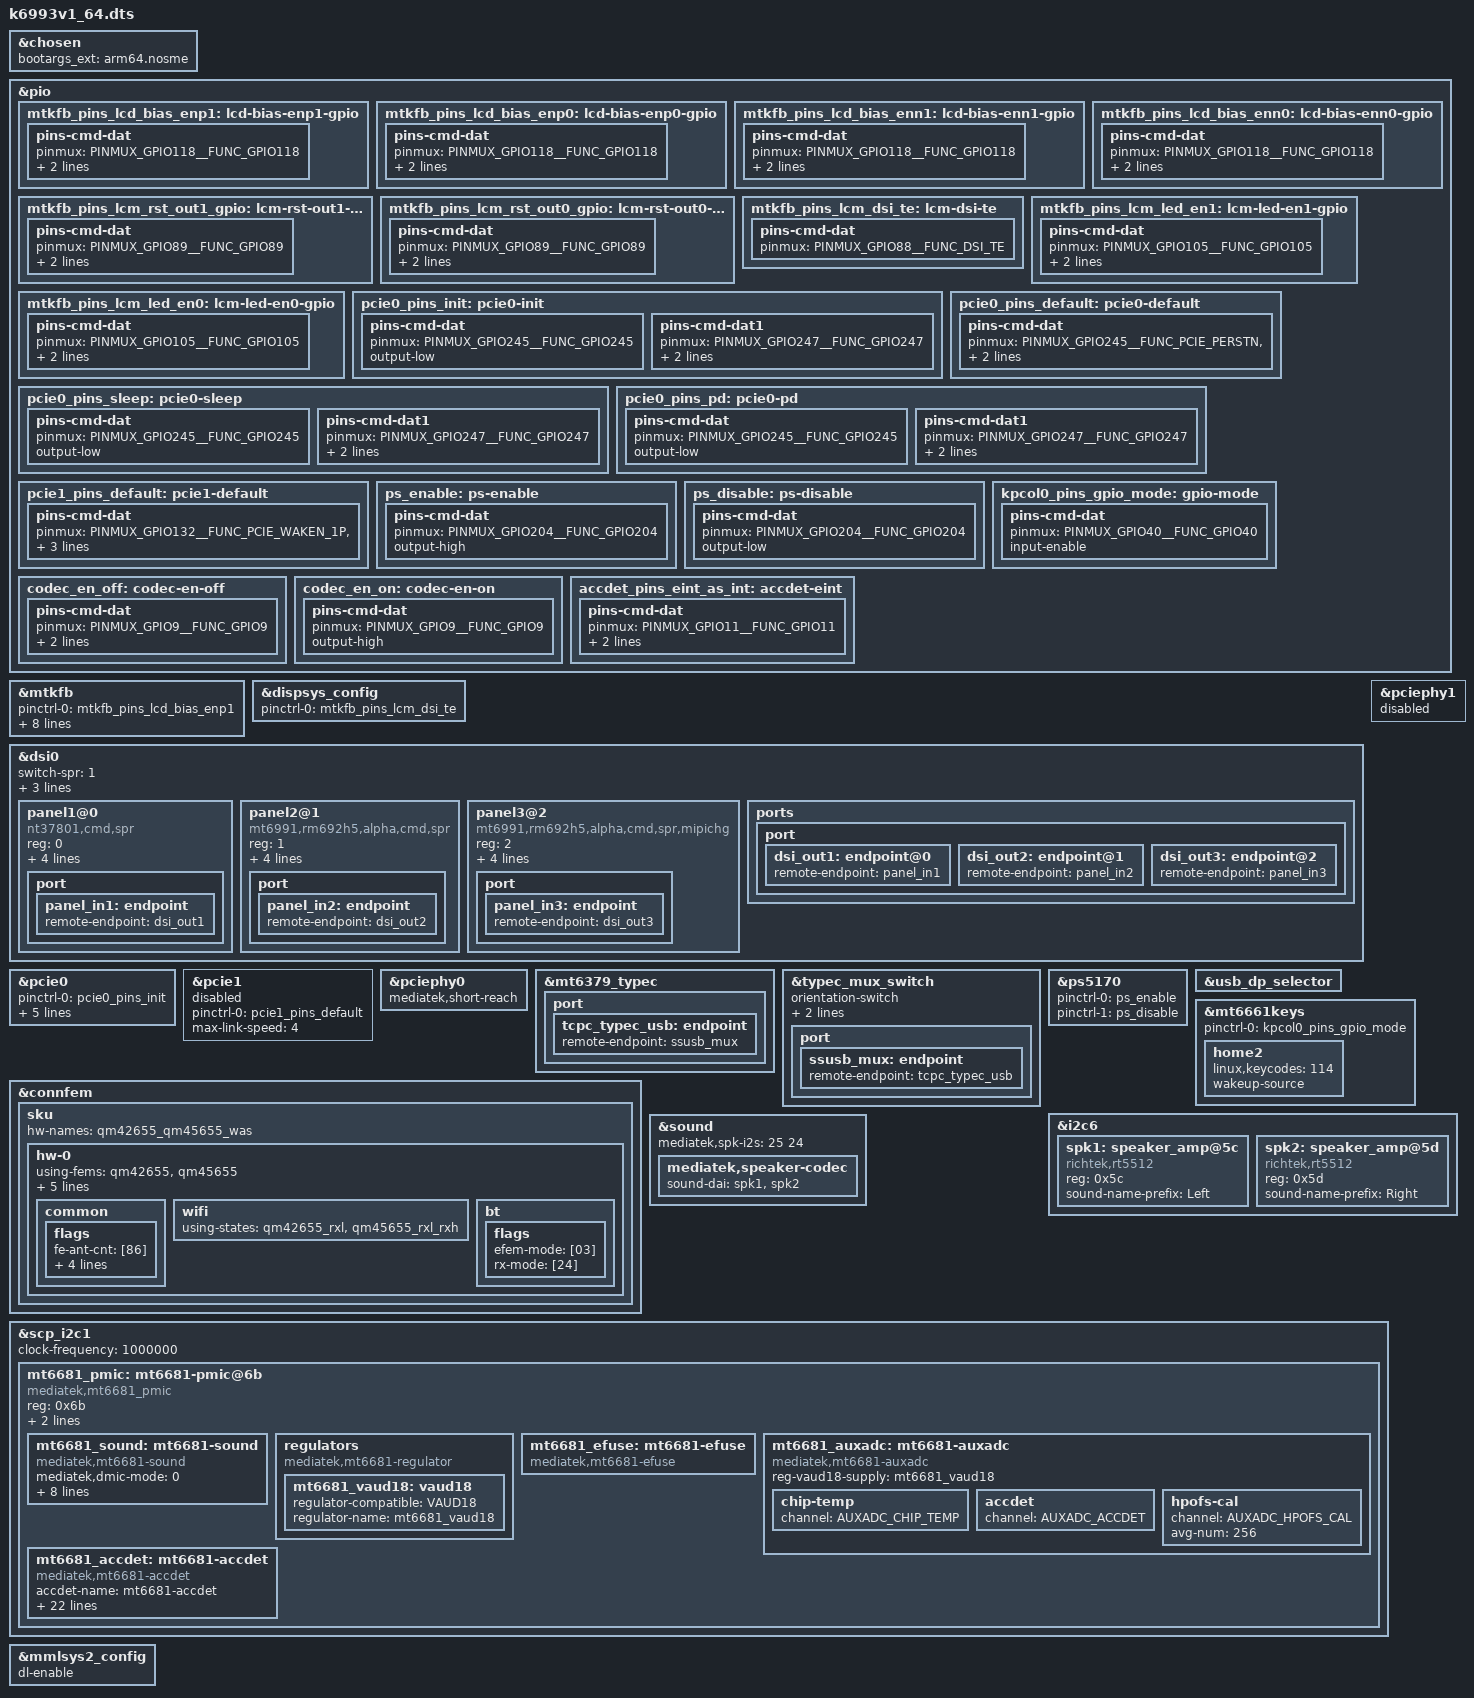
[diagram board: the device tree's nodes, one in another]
// SPDX-License-Identifier: (GPL-2.0 OR MIT)
/*
 * Copyright (C) 2022 MediaTek Inc.
 */
/dts-v1/;
/plugin/;
#include <dt-bindings/interrupt-controller/arm-gic.h>
#include <dt-bindings/interrupt-controller/irq.h>
#include <dt-bindings/pinctrl/mt6993-pinfunc.h>
#include <dt-bindings/phy/phy.h>
#include <dt-bindings/iio/mt635x-auxadc.h>

&chosen {
	bootargs_ext = "arm64.nosme";
};

&pio {
	mtkfb_pins_lcd_bias_enp1: lcd-bias-enp1-gpio {
		pins-cmd-dat {
			pinmux = <PINMUX_GPIO118__FUNC_GPIO118>;
			slew-rate = <1>;
			output-high;
		};
	};
	mtkfb_pins_lcd_bias_enp0: lcd-bias-enp0-gpio {
		pins-cmd-dat {
			pinmux = <PINMUX_GPIO118__FUNC_GPIO118>;
			slew-rate = <1>;
			output-low;
		};
	};
	mtkfb_pins_lcd_bias_enn1: lcd-bias-enn1-gpio {
		pins-cmd-dat {
			pinmux = <PINMUX_GPIO118__FUNC_GPIO118>;
			slew-rate = <1>;
			output-high;
		};
	};
	mtkfb_pins_lcd_bias_enn0: lcd-bias-enn0-gpio {
		pins-cmd-dat {
			pinmux = <PINMUX_GPIO118__FUNC_GPIO118>;
			slew-rate = <1>;
			output-low;
		};
	};
	mtkfb_pins_lcm_rst_out1_gpio: lcm-rst-out1-gpio {
		pins-cmd-dat {
			pinmux = <PINMUX_GPIO89__FUNC_GPIO89>;
			slew-rate = <1>;
			output-high;
		};
	};
	mtkfb_pins_lcm_rst_out0_gpio: lcm-rst-out0-gpio {
		pins-cmd-dat {
			pinmux = <PINMUX_GPIO89__FUNC_GPIO89>;
			slew-rate = <1>;
			output-low;
		};
	};
	mtkfb_pins_lcm_dsi_te: lcm-dsi-te {
		pins-cmd-dat {
			pinmux = <PINMUX_GPIO88__FUNC_DSI_TE>;
		};
	};
	mtkfb_pins_lcm_led_en1: lcm-led-en1-gpio {
		pins-cmd-dat {
			pinmux = <PINMUX_GPIO105__FUNC_GPIO105>;
			slew-rate = <1>;
			output-high;
		};
	};
	mtkfb_pins_lcm_led_en0: lcm-led-en0-gpio {
		pins-cmd-dat {
			pinmux = <PINMUX_GPIO105__FUNC_GPIO105>;
			slew-rate = <1>;
			output-low;
		};
	};
};

&mtkfb {
	pinctrl-names = "lcd_bias_enp1_gpio", "lcd_bias_enp0_gpio",
		"lcd_bias_enn1_gpio", "lcd_bias_enn0_gpio",
		"lcm_rst_out1_gpio", "lcm_rst_out0_gpio",
		"mode_te_te", "lcm_led_en1_gpio", "lcm_led_en0_gpio",
		"mode_te_te1";
	pinctrl-0 = <&mtkfb_pins_lcd_bias_enp1>;
	pinctrl-1 = <&mtkfb_pins_lcd_bias_enp0>;
	pinctrl-2 = <&mtkfb_pins_lcd_bias_enn1>;
	pinctrl-3 = <&mtkfb_pins_lcd_bias_enn0>;
	pinctrl-4 = <&mtkfb_pins_lcm_rst_out1_gpio>;
	pinctrl-5 = <&mtkfb_pins_lcm_rst_out0_gpio>;
	pinctrl-6 = <&mtkfb_pins_lcm_dsi_te>;
	pinctrl-7 = <&mtkfb_pins_lcm_led_en1>;
	pinctrl-8 = <&mtkfb_pins_lcm_led_en0>;
	status = "okay";
};

&dispsys_config {
	pinctrl-names = "mode_te_te";
	pinctrl-0 = <&mtkfb_pins_lcm_dsi_te>;

	status = "okay";
};

&dsi0 {
	status = "okay";
	#address-cells = <1>;
	#size-cells = <0>;
	switch-spr = <1>;
	spr-ip-type = <0>;
	switch-mipi-clk-chg = <0>;
	mte-support = <1>;
	panel1@0 {
		compatible = "nt37801,cmd,spr";
		reg = <0>;
		pm-enable-gpios = <&pio 105 0>;
		reset-gpios = <&pio 89 0>;
		res-switch = <2>;
		gate-ic = <4831>;
		pinctrl-names = "default";
		port {
			panel_in1: endpoint {
				remote-endpoint = <&dsi_out1>;
			};
		};
	};
	panel2@1 {
		compatible = "mt6991,rm692h5,alpha,cmd,spr";
		reg = <1>;
		vddr-gpios = <&pio 105 0>;
		reset-gpios = <&pio 89 0>;
		res-switch = <2>;
		gate-ic = <4831>;
		pinctrl-names = "default";
		port {
			panel_in2: endpoint {
				remote-endpoint = <&dsi_out2>;
			};
		};
	};
	panel3@2 {
		compatible = "mt6991,rm692h5,alpha,cmd,spr,mipichg";
		reg = <2>;
		vddr-gpios = <&pio 105 0>;
		reset-gpios = <&pio 89 0>;
		res-switch = <2>;
		gate-ic = <4831>;
		pinctrl-names = "default";
		port {
			panel_in3: endpoint {
				remote-endpoint = <&dsi_out3>;
			};
		};
	};
	ports {
		port {
			dsi_out1: endpoint@0 {
				remote-endpoint = <&panel_in1>;
			};
			/* dsi_out2 but dsi_out1 fixes warning. It only allows pairing endpoints.*/
			dsi_out2: endpoint@1 {
				remote-endpoint = <&panel_in2>;
			};
			dsi_out3: endpoint@2 {
				remote-endpoint = <&panel_in3>;
			};
		};
	};
};

&pcie0 {
	pinctrl-names = "init", "default", "sleep", "pd";
	pinctrl-0 = <&pcie0_pins_init>;
	pinctrl-1 = <&pcie0_pins_default>;
	pinctrl-2 = <&pcie0_pins_sleep>;
	pinctrl-3 = <&pcie0_pins_pd>;
	max-link-speed = <4>;
	mediatek,suspend-mode-l12;
	status = "okay";
};

&pcie1 {
	pinctrl-names = "default";
	pinctrl-0 = <&pcie1_pins_default>;
	max-link-speed = <4>;
	status = "disabled";
};

&pciephy0 {
	mediatek,short-reach;
	status = "okay";
};

&pciephy1 {
	status = "disabled";
};

/* PCIe pinmux start */
/* skyhawk use waken to control DFD_EN, PCIe0 don't need to control it */
&pio {
	pcie0_pins_init: pcie0-init {
		pins-cmd-dat {
			pinmux = <PINMUX_GPIO245__FUNC_GPIO245>;
			output-low;
		};

		pins-cmd-dat1 {
			pinmux = <PINMUX_GPIO247__FUNC_GPIO247>;
			bias-pull-up;
			input-enable;
		};
	};

	pcie0_pins_default: pcie0-default {
		pins-cmd-dat {
			pinmux = <PINMUX_GPIO245__FUNC_PCIE_PERSTN>,
				 <PINMUX_GPIO247__FUNC_PCIE_CLKREQN>;
			bias-pull-up;
		};
	};

	pcie0_pins_sleep: pcie0-sleep {
		pins-cmd-dat {
			pinmux = <PINMUX_GPIO245__FUNC_GPIO245>;
			output-low;
		};

		pins-cmd-dat1 {
			pinmux = <PINMUX_GPIO247__FUNC_GPIO247>;
			bias-pull-up;
			input-enable;
		};
	};

	pcie0_pins_pd: pcie0-pd {
		pins-cmd-dat {
			pinmux = <PINMUX_GPIO245__FUNC_GPIO245>;
			output-low;
		};

		pins-cmd-dat1 {
			pinmux = <PINMUX_GPIO247__FUNC_GPIO247>;
			bias-pull-down;
			input-enable;
		};
	};

	pcie1_pins_default: pcie1-default {
		pins-cmd-dat {
			pinmux = <PINMUX_GPIO132__FUNC_PCIE_WAKEN_1P>,
				 <PINMUX_GPIO133__FUNC_PCIE_PERSTN_1P>,
				 <PINMUX_GPIO134__FUNC_PCIE_CLKREQN_1P>;
			bias-pull-up;
		};
	};
};
/* PCIe pinmux end */

/* usb typec mux start */
&pio {
	ps_enable: ps-enable {
		pins-cmd-dat {
			pinmux = <PINMUX_GPIO204__FUNC_GPIO204>;
			output-high;
		};
	};

	ps_disable: ps-disable {
		pins-cmd-dat {
			pinmux = <PINMUX_GPIO204__FUNC_GPIO204>;
			output-low;
		};
	};
};

&mt6379_typec {
	port {
		tcpc_typec_usb: endpoint {
			remote-endpoint = <&ssusb_mux>;
		};
	};
};

&typec_mux_switch {
	orientation-switch;
	mode-switch;
	accessory;
	port {
		ssusb_mux: endpoint {
			remote-endpoint = <&tcpc_typec_usb>;
		};
	};
};

&ps5170 {
	pinctrl-names = "enable", "disable";
	pinctrl-0 = <&ps_enable>;
	pinctrl-1 = <&ps_disable>;
	status = "okay";
};

&usb_dp_selector {
	status = "okay";
};
/* usb typec mux end */

&mt6661keys {
	pinctrl-names = "kpcol0_mode";
	pinctrl-0 = <&kpcol0_pins_gpio_mode>;
	home2 {
		linux,keycodes = <114>;
		wakeup-source;
	};
};

&pio {
	kpcol0_pins_gpio_mode: gpio-mode {
		pins-cmd-dat {
			pinmux = <PINMUX_GPIO40__FUNC_GPIO40>;
			input-enable;
		};
	};
};

&connfem {
	sku {
		hw-names =
			"qm42655_qm45655_was";	/* [0] QM42655/QM45655, 2G+2A, BT/Wi-Fi AntSwap */

		/***************************************************************
		 * [HW][0] QM42655/QM45655, 2G+2A, BT/Wi-Fi AntSwap
		 **************************************************************/
		hw-0 {
			using-fems =
				<&qm42655>,
				<&qm45655>;

			layout-flag = <0x00000000>;
			layout =
				<&g_wf0_bt0_qm42655>,
				<&g_wf1_bt1_qm42655>,
				<&a_wf0_qm45655>,
				<&a_wf12_emlsr_bt0_qm45655>;

			layout-spdt =
				<&spdt_a1_a2_tx>,
				<&spdt_a1_a2_rx>,
				<&spdt_a_wf0_antswap>,
				<&spdt_g_bt1_antswap>;

			common {
				flags {
					fe-ant-cnt = [86];
					fe-conn-dpdt-sp3t = [80];
					fe-conn-spdt = [93];
					fe-bt-wf-usage = [80];
					fe-conn-spdt-2 = [90];
				};
			};

			wifi {
				using-states =
					<&qm42655_rxl>,
					<&qm45655_rxl_rxh>;
			};

			bt {
				flags {
					efem-mode = [03]; /* 3:epa_elna, 2:epa, 1:elna, 0:bypass */
					rx-mode = [24]; /* 0x24: G-band RxL */
				};
			};
		};
	};
};

&i2c6 {
	spk1: speaker_amp@5c {
		compatible = "richtek,rt5512";
		#sound-dai-cells = <0>;
		reg = <0x5c>;
		status = "okay";
		sound-name-prefix = "Left";
	};

	spk2: speaker_amp@5d {
		compatible = "richtek,rt5512";
		#sound-dai-cells = <0>;
		reg = <0x5d>;
		status = "okay";
		sound-name-prefix = "Right";
	};
};

&sound {
	mediatek,spk-i2s = <25 24>;
	mediatek,speaker-codec {
		sound-dai = <&spk1>, <&spk2>;
	};
};

&scp_i2c1 {
	clock-frequency = <1000000>;
	#address-cells = <1>;
	#size-cells = <0>;
	mt6681_pmic: mt6681-pmic@6b {
		status = "okay";
		compatible = "mediatek,mt6681_pmic";
		reg = <0x6b>;
	    pinctrl-names = "codec-en-off",
		"codec-en-on";
		pinctrl-0 = <&codec_en_off>;
		pinctrl-1 = <&codec_en_on>;
		mt6681_sound: mt6681-sound {
			compatible = "mediatek,mt6681-sound";
			mediatek,dmic-mode = <0>;
			mediatek,mic-type-0 = <3>;
			mediatek,mic-type-1 = <3>;
			mediatek,mic-type-2 = <3>;
			io-channels = <&mt6681_auxadc AUXADC_HPOFS_CAL>;
			io-channel-names = "pmic_hpofs_cal";
			nvmem = <&mt6681_efuse>;
			nvmem-names = "pmic-hp-efuse";
			reg-vaud18-supply = <&mt6681_vaud18>;
			audio-r-miso1-enable = <1>;
		};
		regulators {
			compatible = "mediatek,mt6681-regulator";
			mt6681_vaud18: vaud18 {
				regulator-compatible = "VAUD18";
				regulator-name = "mt6681_vaud18";
			};
		};
		mt6681_efuse: mt6681-efuse {
			compatible = "mediatek,mt6681-efuse";
			#address-cells = <1>;
			#size-cells = <1>;
		};
		mt6681_auxadc: mt6681-auxadc {
			compatible = "mediatek,mt6681-auxadc";
			#io-channel-cells = <1>;
			reg-vaud18-supply = <&mt6681_vaud18>;
			chip-temp {
				channel = <AUXADC_CHIP_TEMP>;
			};
			accdet {
				channel = <AUXADC_ACCDET>;
			};
			hpofs-cal {
				channel = <AUXADC_HPOFS_CAL>;
				avg-num = <256>;
			};
		};
		mt6681_accdet: mt6681-accdet {
			compatible = "mediatek,mt6681-accdet";
			accdet-name = "mt6681-accdet";
			accdet-mic-vol = <8>;
			accdet-plugout-debounce = <1>;
			accdet-mic-mode = <2>;
			eint-use-ext-res = <0>;
			headset-mode-setting = <0x500 0x500 1 0x1f0
						0x800 0x800 0x20 0x44
						0x4 0x1
						0x5 0x3 0x3 0x5 0xe>;
			headset-use-ap-eint = <0>;
			headset-eint-num = <0>;
			headset-eint-trig-mode = <1>;
			headset-key-mode = <0>;
			headset-three-key-threshold = <0 80 220 400>;
			headset-three-key-threshold-CDD = <0 121 192 600>;
			headset-four-key-threshold = <0 58 121 192 400>;
			io-channels = <&mt6681_auxadc AUXADC_ACCDET>;
			io-channel-names = "pmic_accdet";
			nvmem = <&mt6681_efuse>;
			nvmem-names = "mt63xx-accdet-efuse";
			interrupt-parent = <&pio>;
			interrupts = <11 IRQ_TYPE_LEVEL_LOW>;
			interrupt-names = "ap_eint";
			pinctrl-names = "state_eint_as_int";
			pinctrl-0 = <&accdet_pins_eint_as_int>;
			/*nvmem-cells = <&efuse_spare5>;*/
			/*nvmem-cell-names = "efuse_spare5";*/
			accdet-efuse-check = <0>;
			app-wakelock-time = <1000>;
			accdet-irq-gpio-enable = <1>;
			status = "okay";
		};
	};
};

&pio {
	codec_en_off: codec-en-off {
		pins-cmd-dat {
			pinmux = <PINMUX_GPIO9__FUNC_GPIO9>;
			input-enable;
			bias-pull-down;
		};
	};
	codec_en_on: codec-en-on {
		pins-cmd-dat {
			pinmux = <PINMUX_GPIO9__FUNC_GPIO9>;
			output-high;
		};
	};
};

&pio {
	accdet_pins_eint_as_int: accdet-eint {
		pins-cmd-dat {
			pinmux = <PINMUX_GPIO11__FUNC_GPIO11>;
			bias-pull-up;
			input-enable;
		};
	};
};

&mmlsys2_config {
	dl-enable;
};

#include "k6993v1_64/cust.dtsi"
#include "mediatek/cust_mt6993_camera_v4l2.dtsi"
#include "mediatek/cust_k6993_connfem.dtsi"
#include "mediatek/cust_mt6993_touch_cmd_mult.dtsi"
/*End of this file, DO NOT ADD ANYTHING HERE*/

